# R7KA8P1AD register map
Vendor: Renesas Electronics Corporation; Series: RA8; File version: 1.10.02
CPU: CM85 r0p2, little endian, MPU, FPU, VTOR, 4 interrupt priority bits, 96 interrupts
Registers are 32-bit, read-write, reset 0x0 unless marked. A register's access mark holds for its fields unless they carry their own. Offsets are from the block's base; [hi:lo] are bit positions; {n}, {i} and the like mark numbered series; 'fields as' and 'values as' point back to an identical list.

## WDT0 — Watchdog Timer
Base 0x40202600
Same registers: WDT1 0x40202700, WDT0_NS 0x50202600, WDT1_NS 0x50202700
0x00 WDTRR 8-bit reset 0xFF — WDT Refresh Register
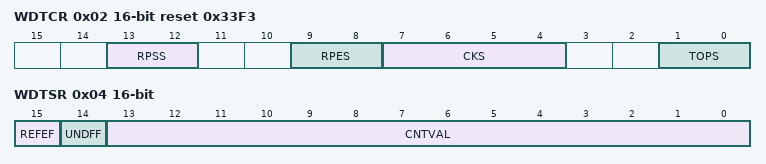
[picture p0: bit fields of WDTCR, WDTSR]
0x02 WDTCR 16-bit reset 0x33F3 — WDT Control Register
  [13:12] RPSS — Window Start Position Select
    0=25%; 1=50%; 2=75%; 3=100% (do not specify window start position)
  [9:8] RPES — Window End Position Select
    0=75%; 1=50%; 2=25%; 3=0% (do not specify window end position)
  [7:4] CKS — Clock Division Ratio Select
    1=PCLKB/4; 4=PCLKB/64; 15=PCLKB/128; 6=PCLKB/512; 7=PCLKB/2048; 8=PCLKB/8192; other=Others (Setting prohibited)
  [1:0] TOPS — Timeout Period Select
    0=1024 cycles (0x03FF); 1=4096 cycles (0x0FFF); 2=8192 cycles (0x1FFF); 3=16384 cycles (0x3FFF)
0x04 WDTSR 16-bit — WDT Status Register
  [15] REFEF — Refresh Error Flag
    0=No refresh error occurred; 1=Refresh error occurred
  [14] UNDFF — Underflow Flag
    0=No underflow occurred; 1=Underflow occurred
  [13:0] CNTVAL ro — Down-Counter Value
0x06 WDTRCR 8-bit reset 0x80 — WDT Reset Control Register
  [7] RSTIRQS — WDT Behavior Selection
    0=Interrupt; 1=Reset
0x08 WDTCSTPR 8-bit reset 0x80 — WDT Count Stop Control Register
  [7] SLCSTP — Sleep-Mode Count Stop Control Register
    0=Disable count stop; 1=Stop count on transition to Sleep mode or Deep Sleep mode

## POEG — Port Output Enable Module for GPT
Base 0x40212000
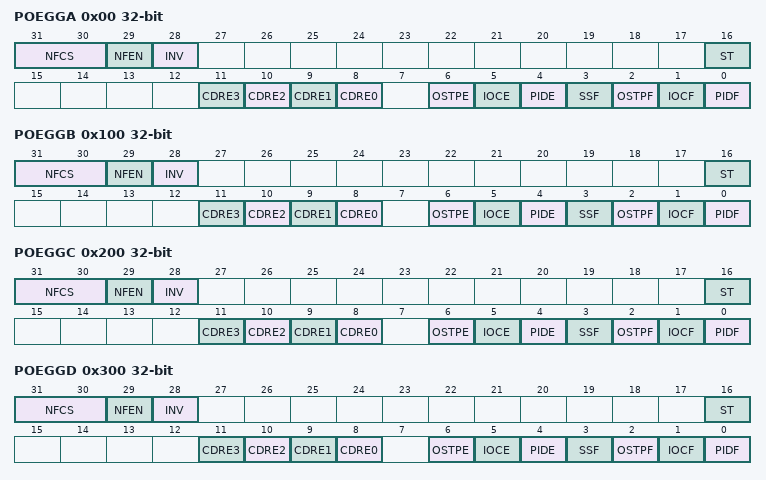
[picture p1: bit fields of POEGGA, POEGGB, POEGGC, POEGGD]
0x00 POEGGA — POEG Group A Setting Register
  [31:30] NFCS — Noise Filter Clock Select
    0=Sample GTETRGn pin input level three times every PCLKB; 1=Sample GTETRGn pin input level three times every PCLKB/8; 2=Sample GTETRGn pin input level three times every PCLKB/32; 3=Sample GTETRGn pin input level three times every PCLKB/128
  [29] NFEN — Noise Filter Enable
    0=Disable noise filtering; 1=Enable noise filtering
  [28] INV — GTETRGn Input Reverse
    0=Input GTETRGn as-is; 1=Input GTETRGn in reverse
  [16] ST ro — GTETRGn Input Status Flag
    0=GTETRGn input after filtering was 0; 1=GTETRGn input after filtering was 1
  [n+8] CDRE{n} (n=0..3)
    0=Disable output-disable request from ACMPHS{n}; 1=Enable output-disable request from ACMPHS{n}
  [6] OSTPE — Oscillation Stop Detection Enable
    0=Disable output-disable requests from oscillation stop detection; 1=Enable output-disable requests from oscillation stop detection
  [5] IOCE — Enable for GPT Output-Disable Request
    0=Disable output-disable requests from GPT; 1=Enable output-disable requests from GPT
  [4] PIDE — Port Input Detection Enable
    0=Disable output-disable requests from the GTETRGn pins; 1=Enable output-disable requests from the GTETRGn pins
  [3] SSF — Software Stop Flag
    0=No output-disable request from software occurred; 1=Output-disable request from software occurred
  [2] OSTPF — Oscillation Stop Detection Flag
    0=No output-disable request from oscillation stop detection occurred; 1=Output-disable request from oscillation stop detection occurred
  [1] IOCF — Detection Flag for GPT or ACMPHS Output-Disable Request
    0=No output-disable request from GPT or comparator interrupt occurred; 1=Output-disable request from GPT or comparator interrupt occurred
  [0] PIDF — Port Input Detection Flag
    0=No output-disable request from the GTETRGn pin occurred; 1=Output-disable request from the GTETRGn pin occurred
0x100 POEGGB — POEG Group B Setting Register
  fields as POEGGA
0x200 POEGGC — POEG Group C Setting Register
  fields as POEGGA
0x300 POEGGD — POEG Group D Setting Register
  fields as POEGGA

## ULPT0
Base 0x40220000
Same registers: ULPT1 0x40220100, ULPT0_NS 0x50220000, ULPT1_NS 0x50220100
0x00 ULPTCNT reset 0xFFFFFFFF — ULPT Counter Register
  [31:0] ULPTCNT — Setting range : 0x00000000 to 0xFFFFFFFF
0x04 ULPTCMA reset 0xFFFFFFFF — ULPT Compare Match A Register
  [31:0] ULPTCMA — 32-bit Compare Match A Data
0x08 ULPTCMB reset 0xFFFFFFFF — ULPT Compare Match B Register
  [31:0] ULPTCMB — 32-bit Compare Match B Data
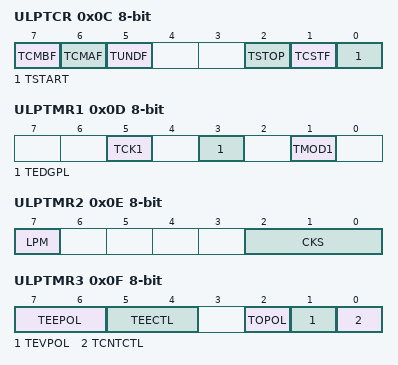
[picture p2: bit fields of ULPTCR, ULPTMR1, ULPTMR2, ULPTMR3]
0x0C ULPTCR 8-bit — ULPT Control Register
  [7] TCMBF — Compare Match B Flag
    0=Not matched (counter ≠ ULPTCMB[31:0]); 1=Matched (counter = ULPTCMB[31:0])
  [6] TCMAF — Compare Match A Flag
    0=Not matched (counter ≠ ULPTCMA[31:0]); 1=Matched (counter = ULPTCMA[31:0])
  [5] TUNDF — Underflow Flag
    0=No underflow occurred (counter ≠ 0x00000000); 1=Underflow occurred (counter = 0x00000000)
  [2] TSTOP wo — Counter Forcible Stop
    0=Writing is invalid; 1=Stop the counter forcibly
  [1] TCSTF ro — Counter Status Flag
    0=Counter stopped; 1=Counter running
  [0] TSTART — Counter Start
    0=Stop the counter; 1=Start the counter
0x0D ULPTMR1 8-bit — ULPT Mode Register 1
  [5] TCK1 — Count Source
    0=Divided clock specified by the ULPTMR2.CKS[2:0] bits (ULPTLCLK); 1=Divided clock specified by the ULPTMR2.CKS[2:0] bits (ULPTSCLK)
  [3] TEDGPL — ULPTEVIn Edge Polarity
    0=Either edge (rising); 1=Both edges
  [1] TMOD1 — Operating Mode
    0=Timer mode; 1=Event counter mode
0x0E ULPTMR2 8-bit — ULPT Mode Register 2
  [7] LPM — Low Power Mode
    0=Normal mode; 1=Low power mode
  [2:0] CKS — ULPTLCLK/ULPTSCLK Count Source Clock Division Ratio
    0=1/1; 1=1/2; 2=1/4; 3=1/8; 4=1/16; 5=1/32; 6=1/64; 7=1/128
0x0F ULPTMR3 8-bit — ULPT Mode Register 3
  [7:6] TEEPOL — ULPTEEn Edge Polarity Select
    0=Rising edge; 1=Falling edge; 2=Both edges
  [5:4] TEECTL — ULPTEEn Function Select
    0=Count enable mode; 2=Count start mode; 3=Count restart mode
  [2] TOPOL — ULPTOn Polarity Select
    0=Start the ULPTOn output when in low level; 1=Start the ULPTOn output when in high level
  [1] TEVPOL — ULPTEVIn Polarity Switch
    0=External event input (ULPTEVIn pin); 1=External event input (ULPTEVIn pin) in reverse
  [0] TCNTCTL — Count Function Select
    0=Continuous mode; 1=One-shot mode
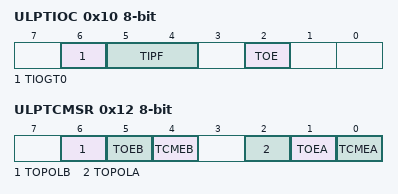
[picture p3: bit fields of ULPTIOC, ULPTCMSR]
0x10 ULPTIOC 8-bit — ULPT I/O Control Register
  [6] TIOGT0 — ULPTEVIn Count Control
    0=Always count external events; 1=Count external events while the ULPTEVIn pin is valid
  [5:4] TIPF — ULPTEVIn Input Filter
    0=No filter; 1=Filter sampling at PCLKB; 2=Filter sampling at PCLKB/8; 3=Filter sampling at PCLKB/32
  [2] TOE — ULPTOn Output Enable
    0=Disable the ULPTOn output; 1=Enable the ULPTOn output
0x11 ULPTISR 8-bit — ULPT Event Pin Select Register
  [2] RCCPSEL2 — ULPTEEn Polarity Select
    0=Count external events when low; 1=Count external events when high
0x12 ULPTCMSR 8-bit — ULPT Compare Match Function Select Register
  [6] TOPOLB — ULPTOBn Polarity Select
    0=Start the ULPTOBn output when low; 1=Start the ULPTOBn output when high
  [5] TOEB — ULPTOBn Output Enable
    0=Disable the ULPTOBn output; 1=Enable the ULPTOBn output
  [4] TCMEB — Compare Match B Register Enable
    0=Disable compare match B register; 1=Enable compare match B register
  [2] TOPOLA — ULPTOAn Polarity Select
    0=Start the ULPTOAn output when low; 1=Start the ULPTOAn output when high
  [1] TOEA — ULPTOAn Output Enable
    0=Disable the ULPTOAn output; 1=Enable the ULPTOAn output
  [0] TCMEA — Compare Match A Register Enable
    0=Disable compare match A register; 1=Enable compare match A register
